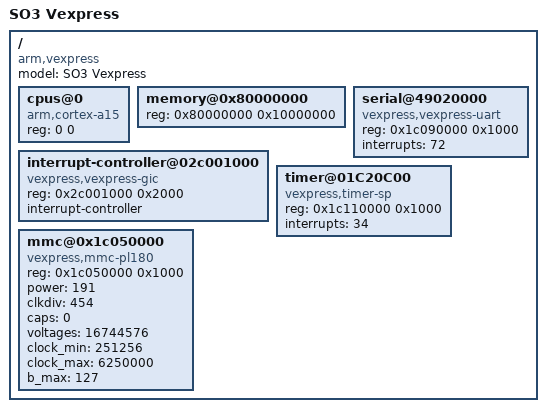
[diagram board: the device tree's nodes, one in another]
/*
 * Copyright (c) 2014, 2015 REDS Institute
 * Copyright (c) 2016, 2017 Sootech SA
 */
 
/dts-v1/;

#include "skeleton.dtsi"

/ {
	model = "SO3 Vexpress";
	compatible = "arm,vexpress";
	
	cpus@0 {
		device_type = "cpu";
		compatible = "arm,cortex-a15";
		reg = <0 0>;
	};

	memory@0x80000000 {
		device_type = "memory";
		reg = <0x80000000 0x10000000>; /* 256 MB */
	};
   
   	/*Vexpress console UART */
	serial@49020000 {
		compatible = "vexpress,vexpress-uart";
		reg = <0x1c090000 0x1000>;
		interrupts = <72>;
		status = "ok";
	};
	
    /* GIC interrupt controller */
    interrupt-controller@02c001000 {
        compatible = "vexpress,vexpress-gic";
        reg = <0x2c001000 0x2000>;
        interrupt-controller;
        status = "ok";
    };
    
    /* System timer */
    timer@01C20C00 {
        compatible = "vexpress,timer-sp";
        reg = <0x1c110000 0x1000>;
        interrupts = <34>;
        status = "ok";
    };
    
	
	/* MMC */
	mmc@0x1c050000 {
		compatible = "vexpress,mmc-pl180";
		reg = <0x1c050000 0x1000>;
		power = <191>;
		clkdiv = <454>;
		caps = <0>;
		voltages = <16744576>;
		clock_min = <251256>;
		clock_max = <6250000>;
		b_max = <127>;
		
		status = "ok";
	};
};
